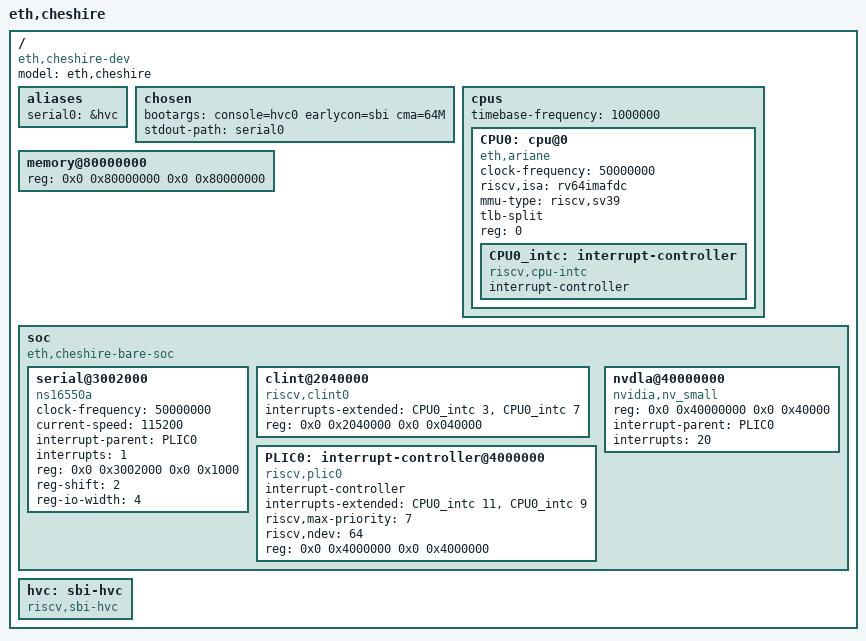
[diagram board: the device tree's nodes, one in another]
/dts-v1/;

// This file is part of https://github.com/celuk/falcon-linux
// Copyright (C) 2026  Seyyid Hikmet Celik
//                     seyyid4091@gmail.com
//
// This program is free software: you can redistribute it and/or modify
// it under the terms of the GNU General Public License as published by
// the Free Software Foundation, either version 3 of the License, or
// (at your option) any later version.
// 
// This program is distributed in the hope that it will be useful,
// but WITHOUT ANY WARRANTY; without even the implied warranty of
// MERCHANTABILITY or FITNESS FOR A PARTICULAR PURPOSE.  See the
// GNU General Public License for more details.
// 
// You should have received a copy of the GNU General Public License
// along with this program.  If not, see <https://www.gnu.org/licenses/>.

// keep off device tree itself from linux space
/memreserve/ 0x80140000 0x00010000;

/ {
	#address-cells = <2>;
	#size-cells = <2>;

	compatible = "eth,cheshire-dev";
  	model = "eth,cheshire";

	aliases {
		serial0 = &hvc;
	};

	chosen {
		bootargs = "console=hvc0 earlycon=sbi cma=64M";
		stdout-path = "serial0";
	};
  // bootargs = "console=hvc0 earlycon=sbi clk_ignore_unused";

	// chosen: chosen {
    //   #address-cells = <2>;
    //   #size-cells = <2>;
    //   ranges;
    //   stdout-path = "/soc/serial@3002000:115200";
    // };
	// bootargs = "console=ttyS0,115200 earlycon=sbi";

	cpus {
      #address-cells = <1>;
      #size-cells = <0>;
      timebase-frequency = <1000000>;
      CPU0: cpu@0 {
        device_type = "cpu";
        status = "okay";
        compatible = "eth,ariane", "riscv";
        clock-frequency = <50000000>;
        riscv,isa = "rv64imafdc";
        mmu-type = "riscv,sv39";
        tlb-split;
        reg = <0>;
        CPU0_intc: interrupt-controller {
          #address-cells = <0>;
          #interrupt-cells = <1>;
          interrupt-controller;
          compatible = "riscv,cpu-intc";
        };
      };
    };

	memory@80000000 {
    	device_type = "memory";
      	reg = <0x0 0x80000000 0x0 0x80000000>; // 2GB memory
  	};

	soc: soc {
      #address-cells = <2>;
      #size-cells = <2>;
      compatible = "eth,cheshire-bare-soc", "simple-bus";
      ranges;
      serial@3002000 {
        compatible = "ns16550a";
        clock-frequency = <50000000>;
        current-speed = <115200>;
        interrupt-parent = <&PLIC0>;
        interrupts = <1>;
        reg = <0x0 0x3002000 0x0 0x1000>;
        reg-shift = <2>; // regs are spaced on 32 bit boundary
        reg-io-width = <4>; // only 32-bit access are supported
      };
      clint@2040000 {
        compatible = "riscv,clint0";
        interrupts-extended = <&CPU0_intc 3 &CPU0_intc 7>;
        reg-names = "control";
        reg = <0x0 0x2040000 0x0 0x040000>;
      };
      PLIC0: interrupt-controller@4000000 {
        compatible = "riscv,plic0", "sifive,plic-1.0.0";
        #address-cells = <0>;
        #interrupt-cells = <1>;
        interrupt-controller;
        interrupts-extended = <&CPU0_intc 11 &CPU0_intc 9>;
        riscv,max-priority = <7>;
        riscv,ndev = <64>;
        reg = <0x0 0x4000000 0x0 0x4000000>;
      };
      nvdla@40000000 {
        compatible = "nvidia,nv_small", "nvidia,nvdla_2", "nvidia,nvdla", "nvidia,nvdla-1";
        reg = <0x0 0x40000000 0x0 0x40000>;
        interrupt-parent = <&PLIC0>;
        interrupts = <20>;
      };
    };

	hvc: sbi-hvc {
		compatible = "riscv,sbi-hvc";
	};
};
